# HC32M458 register map
File version: 1.0
CPU: CM4 r0p1, little endian, MPU, FPU, 4 interrupt priority bits
Registers are 16-bit, read-write, reset 0x0 unless marked. A register's access mark holds for its fields unless they carry their own. Offsets are from the block's base; [hi:lo] are bit positions; {n}, {i} and the like mark numbered series.

## ADC1
Base 0x40040000
0x00 STR 8-bit
  [0] STRT
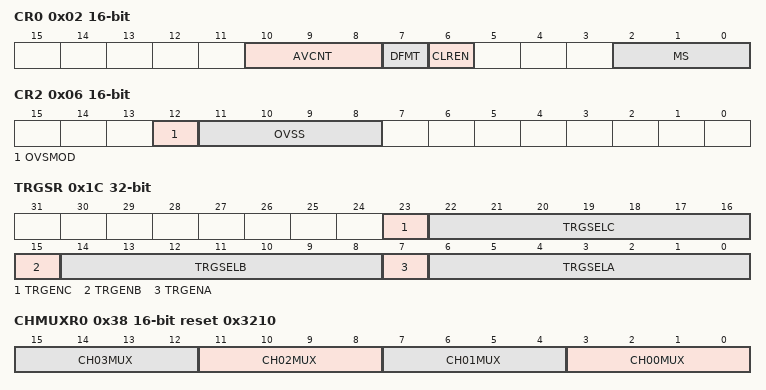
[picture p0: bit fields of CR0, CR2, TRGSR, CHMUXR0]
0x02 CR0
  [10:8] AVCNT, [7] DFMT, [6] CLREN, [2:0] MS
0x04 CR1 reset 0xC0
  [2] RSCHSEL
0x06 CR2
  [12] OVSMOD, [11:8] OVSS
0x0C CHSELRA 32-bit
  [15:0] CHSELA
0x10 CHSELRB 32-bit
  [15:0] CHSELB
0x14 AVCHSELR 32-bit
  [15:0] AVCHSEL
0x18 EXCHSELR 8-bit
  [1:0] EXCHSEL
0x1C TRGSR 32-bit
  [23] TRGENC, [22:16] TRGSELC, [15] TRGENB, [14:8] TRGSELB, [7] TRGENA, [6:0] TRGSELA
{0x20+i} SSTR{i} 8-bit reset 0x4 (i=0..15)
0x38 CHMUXR0 reset 0x3210
  [4n+3:4n] CH{n:02}MUX (n=0..3)
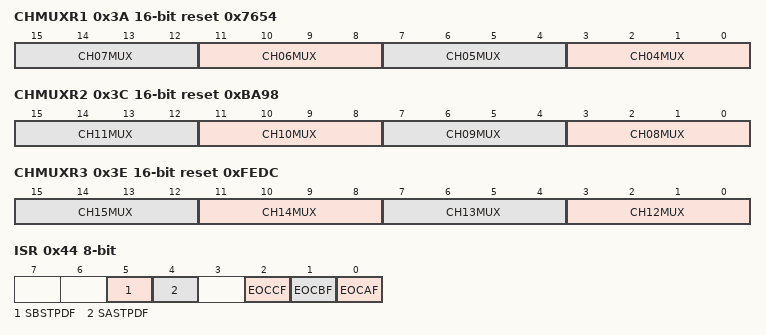
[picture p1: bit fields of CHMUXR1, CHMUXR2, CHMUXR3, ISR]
0x3A CHMUXR1 reset 0x7654
  [4n-13:4n-16] CH{n:02}MUX (n=4..7)
0x3C CHMUXR2 reset 0xBA98
  [4n-29:4n-32] CH{n:02}MUX (n=8..11)
0x3E CHMUXR3 reset 0xFEDC
  [4n-45:4n-48] CH{n}MUX (n=12..15)
0x40 CHSELRC 32-bit
  [15:0] CHSELC
0x44 ISR 8-bit ro
  [5] SBSTPDF, [4] SASTPDF, [2] EOCCF, [1] EOCBF, [0] EOCAF
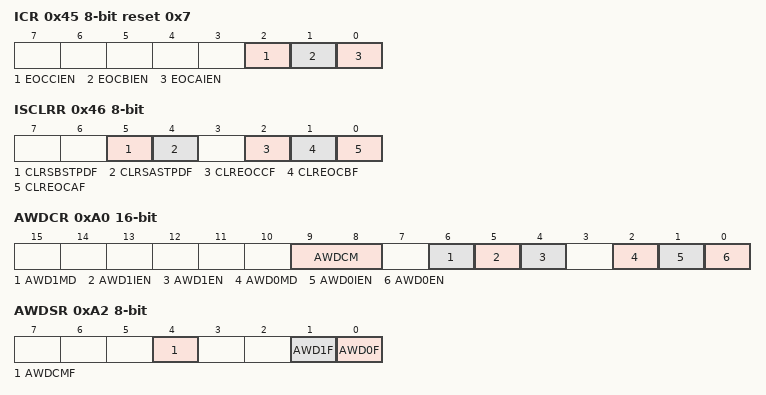
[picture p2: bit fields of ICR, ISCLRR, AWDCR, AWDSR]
0x45 ICR 8-bit reset 0x7
  [2] EOCCIEN, [1] EOCBIEN, [0] EOCAIEN
0x46 ISCLRR 8-bit wo
  [5] CLRSBSTPDF, [4] CLRSASTPDF, [2] CLREOCCF, [1] CLREOCBF, [0] CLREOCAF
{0x50+2i} DR{i} ro (i=0..15)
0xA0 AWDCR
  [9:8] AWDCM, [6] AWD1MD, [5] AWD1IEN, [4] AWD1EN, [2] AWD0MD, [1] AWD0IEN, [0] AWD0EN
0xA2 AWDSR 8-bit ro
  [4] AWDCMF, [1] AWD1F, [0] AWD0F
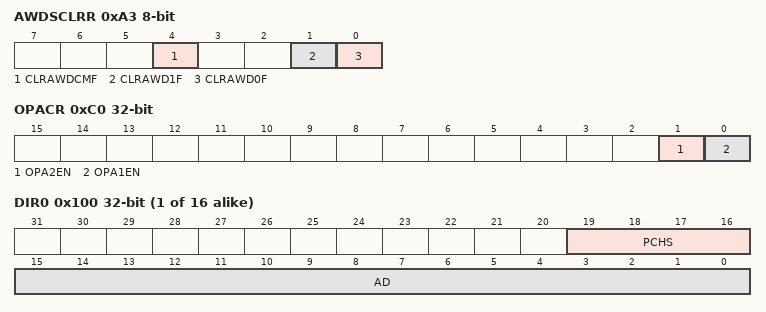
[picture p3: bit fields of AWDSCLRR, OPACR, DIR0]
0xA3 AWDSCLRR 8-bit wo
  [4] CLRAWDCMF, [1] CLRAWD1F, [0] CLRAWD0F
0xA4 AWD0DR0
0xA6 AWD0DR1 reset 0xFFFF
0xA8 AWD0CHSR 8-bit
  [4:0] AWDCH
0xAC AWD1DR0
0xAE AWD1DR1 reset 0xFFFF
0xB0 AWD1CHSR 8-bit
  [4:0] AWDCH
0xC0 OPACR 32-bit
  [1] OPA2EN, [0] OPA1EN
{0x100+4i} DIR{i} 32-bit ro (i=0..15)
  [19:16] PCHS, [15:0] AD

## ADC2
Base 0x40040400
Registers as ADC1, without EXCHSELR, SSTR{n} (n=9..15), DR{n} (n=9..15), OPACR, DIR{n} (n=9..15); these are added or differ:
0x0C CHSELRA 32-bit
  [8:0] CHSELA
0x10 CHSELRB 32-bit
  [8:0] CHSELB
0x14 AVCHSELR 32-bit
  [8:0] AVCHSEL
0x18 ADC_EXCHSELR 8-bit
  [1:0] EXCHSEL
0x40 CHSELRC 32-bit
  [8:0] CHSELC

## AOS
Base 0x40010800
0x00 INTSFTTRG 32-bit wo
  [0] STRG
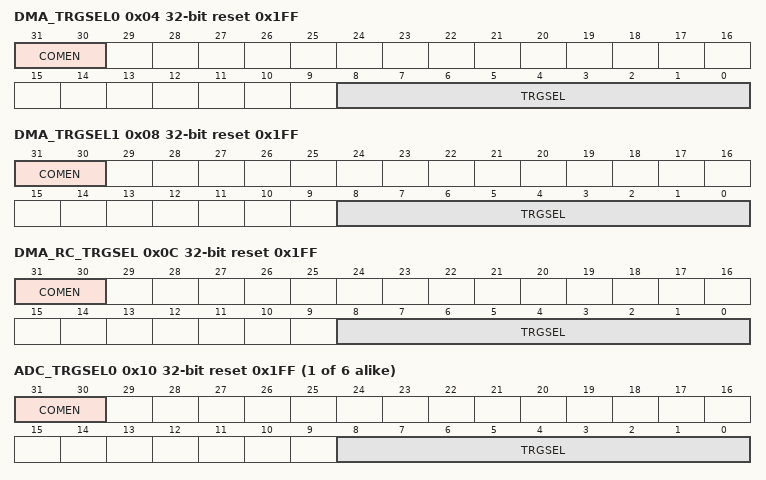
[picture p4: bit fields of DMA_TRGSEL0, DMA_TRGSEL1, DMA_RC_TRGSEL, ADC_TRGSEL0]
0x04 DMA_TRGSEL0 32-bit reset 0x1FF
  [31:30] COMEN, [8:0] TRGSEL
0x08 DMA_TRGSEL1 32-bit reset 0x1FF
  [31:30] COMEN, [8:0] TRGSEL
0x0C DMA_RC_TRGSEL 32-bit reset 0x1FF
  [31:30] COMEN, [8:0] TRGSEL
{0x10+4i} ADC_TRGSEL{i} 32-bit reset 0x1FF (i=0..5)
  [31:30] COMEN, [8:0] TRGSEL
0x28 COMTRGSEL1 32-bit reset 0x1FF
  [8:0] TRGSEL
0x2C COMTRGSEL2 32-bit reset 0x1FF
  [8:0] TRGSEL

## CMP1 — desc CMP
Base 0x40038800
Same registers: CMP2 0x40038900
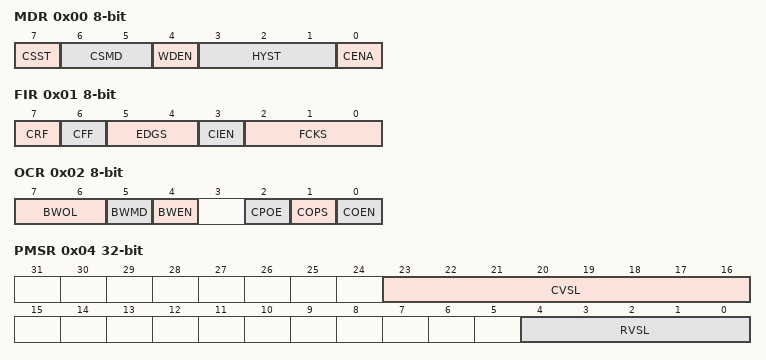
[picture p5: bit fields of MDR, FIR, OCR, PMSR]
0x00 MDR 8-bit
  [7] CSST, [6:5] CSMD, [4] WDEN, [3:1] HYST, [0] CENA
0x01 FIR 8-bit
  [7] CRF, [6] CFF, [5:4] EDGS, [3] CIEN, [2:0] FCKS
0x02 OCR 8-bit
  [7:6] BWOL, [5] BWMD, [4] BWEN, [2] CPOE, [1] COPS, [0] COEN
0x03 OMR 8-bit ro
  [0] CMON
0x04 PMSR 32-bit
  [23:16] CVSL, [4:0] RVSL
0x0C DADR
  [7:0] DADR
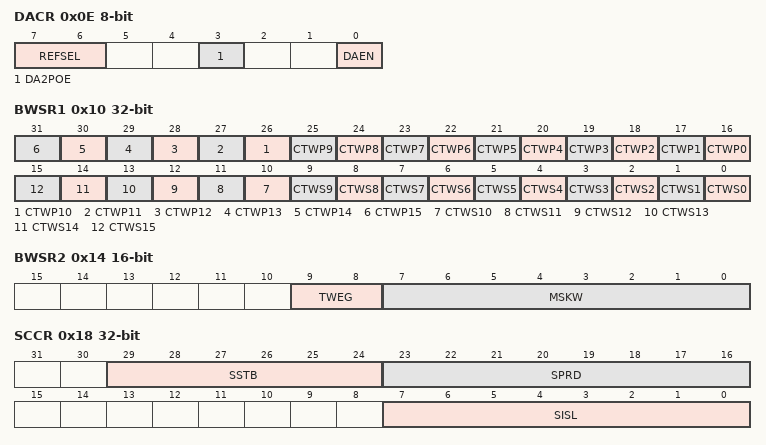
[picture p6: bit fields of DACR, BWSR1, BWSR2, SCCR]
0x0E DACR 8-bit
  [7:6] REFSEL, [3] DA2POE, [0] DAEN
0x10 BWSR1 32-bit
  [n+16] CTWP{n} (n=0..15), [n] CTWS{n} (n=0..15)
0x14 BWSR2
  [9:8] TWEG, [7:0] MSKW
0x18 SCCR 32-bit
  [29:24] SSTB, [23:16] SPRD, [7:0] SISL
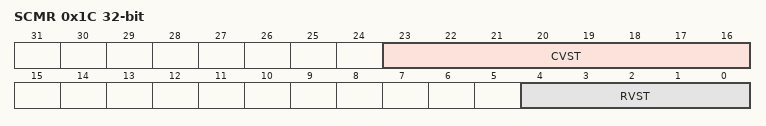
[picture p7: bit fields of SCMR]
0x1C SCMR 32-bit
  [23:16] CVST, [4:0] RVST

## CMU
Base 0x40054000
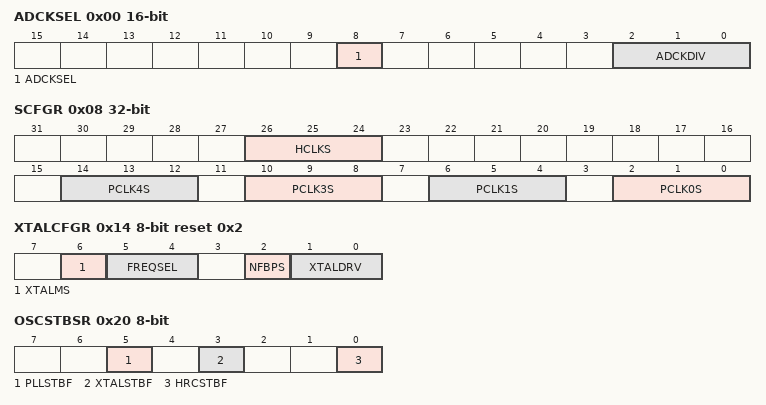
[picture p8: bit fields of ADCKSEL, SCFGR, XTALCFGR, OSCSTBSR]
0x00 ADCKSEL
  [8] ADCKSEL, [2:0] ADCKDIV
0x04 XTALSTDSR 8-bit
  [0] XTALSTDF
0x08 SCFGR 32-bit
  [26:24] HCLKS, [14:12] PCLK4S, [10:8] PCLK3S, [6:4] PCLK1S, [2:0] PCLK0S
0x0C CKSWR 8-bit reset 0x1
  [2:0] CKSW
0x10 XTALCR 8-bit reset 0x1
  [0] XTALSTP
0x14 XTALCFGR 8-bit reset 0x2
  [6] XTALMS, [5:4] FREQSEL, [2] NFBPS, [1:0] XTALDRV
0x15 XTALSTBCR 8-bit
  [2:0] XTALSTB
0x18 HRCCR 8-bit
  [0] HRCSTP
0x20 OSCSTBSR 8-bit ro
  [5] PLLSTBF, [3] XTALSTBF, [0] HRCSTBF
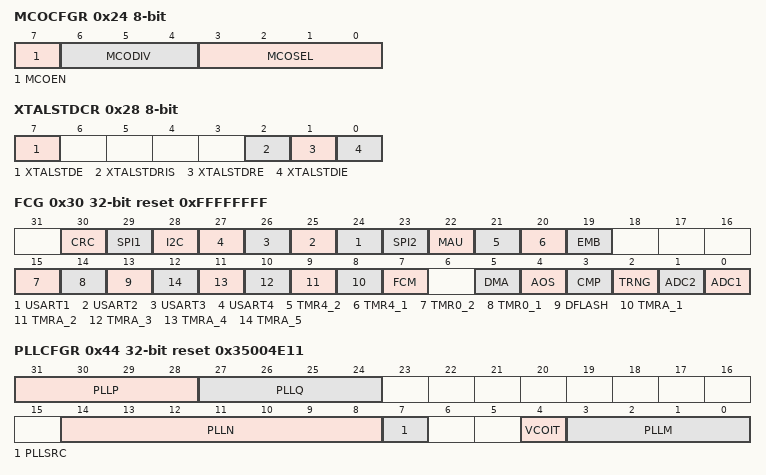
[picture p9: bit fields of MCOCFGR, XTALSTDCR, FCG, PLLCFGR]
0x24 MCOCFGR 8-bit
  [7] MCOEN, [6:4] MCODIV, [3:0] MCOSEL
0x28 XTALSTDCR 8-bit
  [7] XTALSTDE, [2] XTALSTDRIS, [1] XTALSTDRE, [0] XTALSTDIE
0x30 FCG 32-bit reset 0xFFFFFFFF
  [30] CRC, [29] SPI1, [28] I2C, [n+23] USART{n} (n=1..4), [23] SPI2, [22] MAU, [21] TMR4_2, [20] TMR4_1, [19] EMB, [15] TMR0_2, [14] TMR0_1, [13] DFLASH, [n+7] TMRA_{n} (n=1..5), [7] FCM, [5] DMA, [4] AOS, [3] CMP, [2] TRNG, [1] ADC2, [0] ADC1
0x3C LRCCR 8-bit
  [0] LRCSTP
0x40 MRCCR 8-bit
  [0] MRCSTP
0x44 PLLCFGR 32-bit reset 0x35004E11
  [31:28] PLLP, [27:24] PLLQ, [14:8] PLLN, [7] PLLSRC, [4] VCOIT, [3:0] PLLM
0x48 PLLCR 8-bit reset 0x1
  [0] PLLOFF
